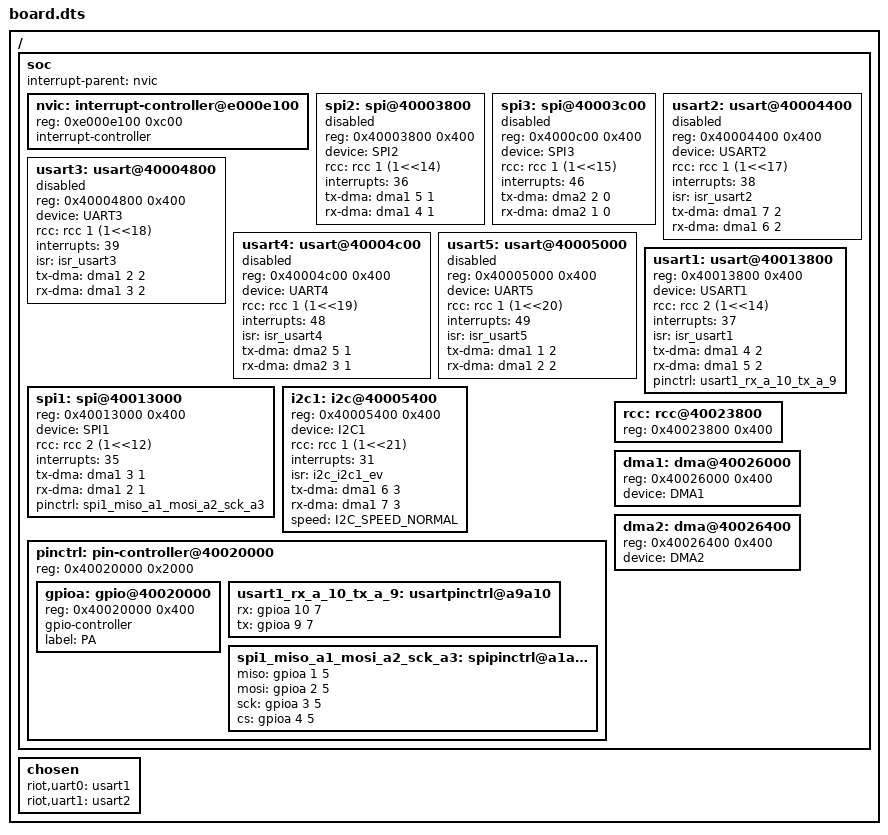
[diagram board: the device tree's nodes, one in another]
/dts-v1/;
/ {
    soc {
        #address-cells = <1>;
        #size-cells = <1>;
        interrupt-parent = <&nvic>;
        nvic: interrupt-controller@e000e100 {
            reg = <0xe000e100 0xc00>;
            interrupt-controller;
            #interrupt-cells = <1>;
        };
    };
};
/ {
    soc {
        spi2: spi@40003800 {
            reg = <0x40003800 0x400>;
            device = "SPI2";
            rcc = <&rcc 1 (1<<14)>;
            interrupts = <36>;
            tx-dma = <&dma1 5 1>;
            rx-dma = <&dma1 4 1>;
            status = "disabled";
        };
        spi3: spi@40003c00 {
            reg = <0x4000c00 0x400>;
            device = "SPI3";
            rcc = <&rcc 1 (1<<15)>;
            interrupts = <46>;
            tx-dma = <&dma2 2 0>;
            rx-dma = <&dma2 1 0>;
            status = "disabled";
        };
        usart2: usart@40004400 {
            reg = <0x40004400 0x400>;
            device = "USART2";
            rcc = <&rcc 1 (1<<17)>;
            interrupts = <38>;
            isr = "isr_usart2";
            tx-dma = <&dma1 7 2>;
            rx-dma = <&dma1 6 2>;
            status = "disabled";
        };
        usart3: usart@40004800 {
            reg = <0x40004800 0x400>;
            device = "UART3";
            rcc = <&rcc 1 (1<<18)>;
            interrupts = <39>;
            isr = "isr_usart3";
            tx-dma = <&dma1 2 2>;
            rx-dma = <&dma1 3 2>;
            status = "disabled";
        };
        usart4: usart@40004c00 {
            reg = <0x40004c00 0x400>;
            device = "UART4";
            rcc = <&rcc 1 (1<<19)>;
            interrupts = <48>;
            isr = "isr_usart4";
            tx-dma = <&dma2 5 1>;
            rx-dma = <&dma2 3 1>;
            status = "disabled";
        };
        usart5: usart@40005000 {
            reg = <0x40005000 0x400>;
            device = "UART5";
            rcc = <&rcc 1 (1<<20)>;
            interrupts = <49>;
            isr = "isr_usart5";
            tx-dma = <&dma1 1 2>;
            rx-dma = <&dma1 2 2>;
            status = "disabled";
        };
        spi1: spi@40013000 {
            reg = <0x40013000 0x400>;
            device = "SPI1";
            rcc = <&rcc 2 (1<<12)>;
            interrupts = <35>;
            tx-dma = <&dma1 3 1>;
            rx-dma = <&dma1 2 1>;
            status = "disabled";
        };
        usart1: usart@40013800 {
            reg = <0x40013800 0x400>;
            device = "USART1";
            rcc = <&rcc 2 (1<<14)>;
            interrupts = <37>;
            isr = "isr_usart1";
            tx-dma = <&dma1 4 2>;
            rx-dma = <&dma1 5 2>;
            status = "disabled";
        };
        i2c1: i2c@40005400 {
            reg = <0x40005400 0x400>;
            #address-cells = <1>;
            #size-cells = <0>;
            device = "I2C1";
            rcc = <&rcc 1 (1<<21)>;
            interrupts = <31>;
            isr = "i2c_i2c1_ev";
            tx-dma = <&dma1 6 3>;
            rx-dma = <&dma1 7 3>;
            speed = "I2C_SPEED_NORMAL";
            status = "disabled";
        };
        pinctrl: pin-controller@40020000 {
            #address-cells = <1>;
            #size-cells = <1>;
            reg = <0x40020000 0x2000>;
            gpioa: gpio@40020000 {
                reg = <0x40020000 0x400>;
                gpio-controller;
                #gpio-cells = <2>;
                label = "PA";
            };
        };
        rcc: rcc@40023800 {
            reg = <0x40023800 0x400>;
            #clock-cells = <2>;
        };
        dma1: dma@40026000 {
            reg = <0x40026000 0x400>;
            device = "DMA1";
            #dma-cells = <2>;
        };
        dma2: dma@40026400 {
            reg = <0x40026400 0x400>;
            device = "DMA2";
            #dma-cells = <2>;
        };
    };
};
/ {
    chosen {
        riot,uart0 = <&usart1>;
        riot,uart1 = <&usart2>;
    };
};
&pinctrl {
    usart1_rx_a_10_tx_a_9: usartpinctrl@a9a10 {
        rx = <&gpioa 10 7>;
        tx = <&gpioa 9 7>;
    };
    spi1_miso_a1_mosi_a2_sck_a3: spipinctrl@a1a2a3 {
        miso = <&gpioa 1 5>;
        mosi = <&gpioa 2 5>;
        sck = <&gpioa 3 5>;
        cs = <&gpioa 4 5>;
    };
};
&usart1 {
    status = "okay";
    pinctrl = <&usart1_rx_a_10_tx_a_9>;
};
&spi1 {
    status = "okay";
    pinctrl = <&spi1_miso_a1_mosi_a2_sck_a3>;
};
&i2c1 {
    status = "okay";
};
